# SWM320 register map
File version: 1.0
CPU: CM0 r1p0, little endian, 2 interrupt priority bits
Registers are 32-bit, read-write, no defined reset value unless marked. A register's access mark holds for its fields unless they carry their own. Offsets are from the block's base; [hi:lo] are bit positions; lines under a group give offsets from that group; {n}, {i} and the like mark numbered series; 'fields as' and 'values as' point back to an identical list.

## PWMG — Registers group
Base 0x4001A180
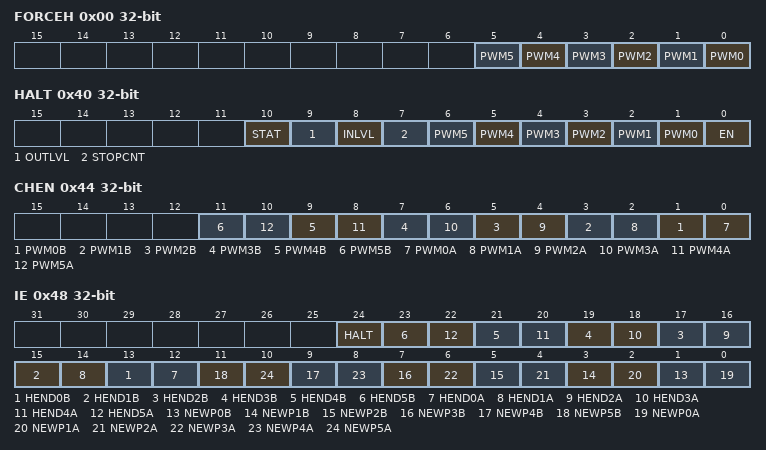
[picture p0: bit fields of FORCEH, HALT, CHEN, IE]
0x00 FORCEH
  [n] PWM{n} (n=0..5)
{0x4+8i} ADTRG{i}A (i=0..5)
{0x8+8i} ADTRG{i}B (i=0..5)
0x40 HALT
  [10] STAT, [9] OUTLVL, [8] INLVL, [7] STOPCNT, [n+1] PWM{n} (n=0..5), [0] EN
0x44 CHEN
  [2n+1] PWM{n}B (n=0..5), [2n] PWM{n}A (n=0..5)
0x48 IE
  [24] HALT, [2n+13] HEND{n}B (n=0..5), [2n+12] HEND{n}A (n=0..5), [2n+1] NEWP{n}B (n=0..5), [2n] NEWP{n}A (n=0..5)
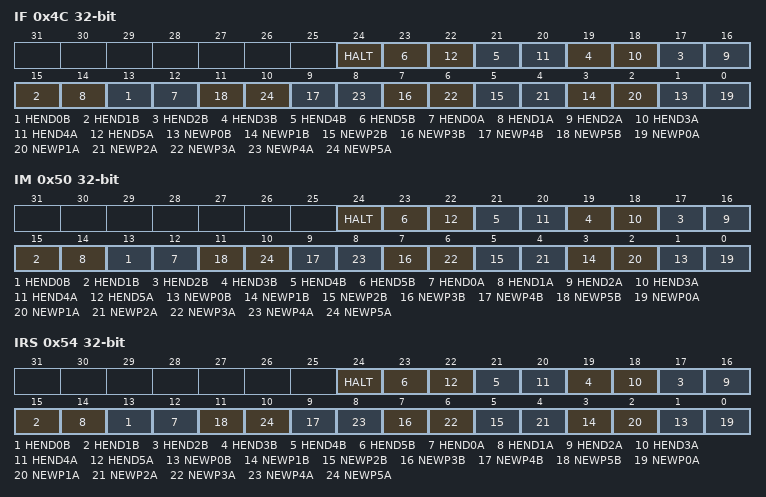
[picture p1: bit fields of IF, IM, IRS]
0x4C IF
  fields as IE
0x50 IM
  fields as IE
0x54 IRS
  fields as IE

## SDIO — Registers group
Base 0x40004000
0x00 DMA_MEM_ADDR
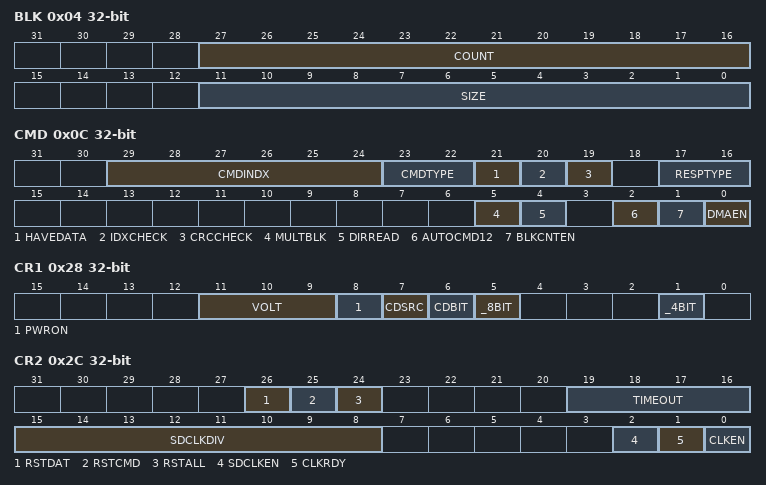
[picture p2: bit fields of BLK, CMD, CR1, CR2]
0x04 BLK
  [27:16] COUNT, [11:0] SIZE
0x08 ARG
0x0C CMD
  [29:24] CMDINDX, [23:22] CMDTYPE, [21] HAVEDATA, [20] IDXCHECK, [19] CRCCHECK, [17:16] RESPTYPE, [5] MULTBLK, [4] DIRREAD, [2] AUTOCMD12, [1] BLKCNTEN, [0] DMAEN
{0x10+4i} RESP[{i}] (i=0..3)
0x20 DATA
0x24 STAT
0x28 CR1
  [11:9] VOLT, [8] PWRON, [7] CDSRC, [6] CDBIT, [5] _8BIT, [1] _4BIT
0x2C CR2
  [26] RSTDAT, [25] RSTCMD, [24] RSTALL, [19:16] TIMEOUT, [15:8] SDCLKDIV, [2] SDCLKEN, [1] CLKRDY, [0] CLKEN
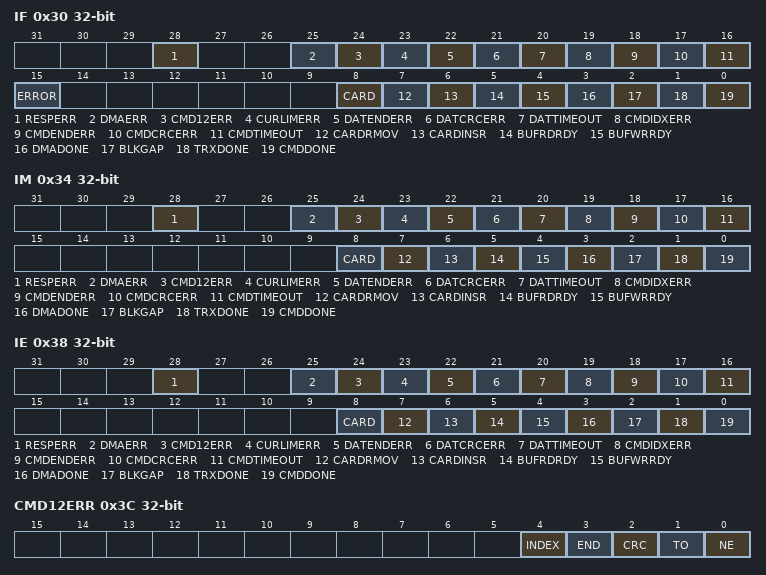
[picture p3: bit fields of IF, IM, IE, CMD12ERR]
0x30 IF
  [28] RESPERR, [25] DMAERR, [24] CMD12ERR, [23] CURLIMERR, [22] DATENDERR, [21] DATCRCERR, [20] DATTIMEOUT, [19] CMDIDXERR, [18] CMDENDERR, [17] CMDCRCERR, [16] CMDTIMEOUT, [15] ERROR, [8] CARD, [7] CARDRMOV, [6] CARDINSR, [5] BUFRDRDY, [4] BUFWRRDY, [3] DMADONE, [2] BLKGAP, [1] TRXDONE, [0] CMDDONE
0x34 IM
  [28] RESPERR, [25] DMAERR, [24] CMD12ERR, [23] CURLIMERR, [22] DATENDERR, [21] DATCRCERR, [20] DATTIMEOUT, [19] CMDIDXERR, [18] CMDENDERR, [17] CMDCRCERR, [16] CMDTIMEOUT, [8] CARD, [7] CARDRMOV, [6] CARDINSR, [5] BUFRDRDY, [4] BUFWRRDY, [3] DMADONE, [2] BLKGAP, [1] TRXDONE, [0] CMDDONE
0x38 IE
  fields as IM
0x3C CMD12ERR
  [4] INDEX, [3] END, [2] CRC, [1] TO, [0] NE

## DMA — Registers group
Base 0x40001000
0x00 EN
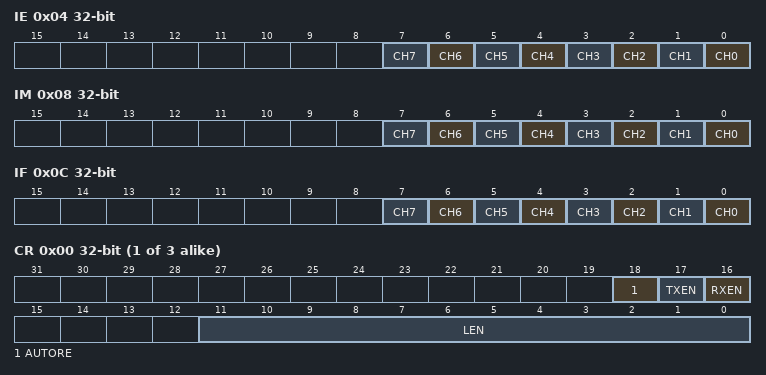
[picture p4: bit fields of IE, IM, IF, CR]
0x04 IE
  [n] CH{n} (n=0..7)
0x08 IM
  [n] CH{n} (n=0..7)
0x0C IF
  [n] CH{n} (n=0..7)
{0x40+0x40*i} CH{i} group (i=0..2) — register cluster
  0x00 CR
    [18] AUTORE, [17] TXEN, [16] RXEN, [11:0] LEN
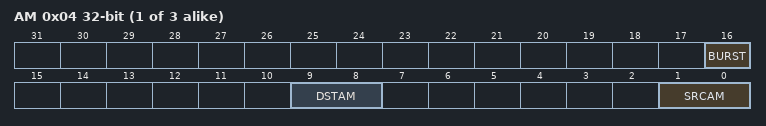
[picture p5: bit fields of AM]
  0x04 AM
    [16] BURST, [9:8] DSTAM, [1:0] SRCAM
  0x08 SRC
  {0x8+4j} SRCSGADDR{j} (j=1..3)
  0x18 SRCSGLEN
  0x1C DST
  {0x1C+4j} DSTSGADDR{j} (j=1..3)
  0x2C DSTSGLEN

## CAN — Registers group
Base 0x40030000
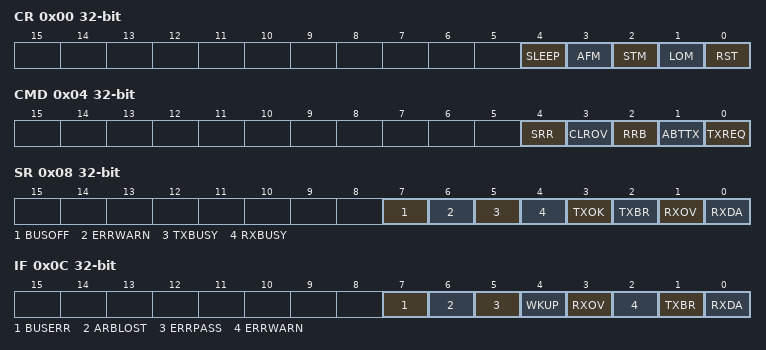
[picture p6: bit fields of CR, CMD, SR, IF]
0x00 CR
  [4] SLEEP, [3] AFM, [2] STM, [1] LOM, [0] RST
0x04 CMD wo
  [4] SRR, [3] CLROV, [2] RRB, [1] ABTTX, [0] TXREQ
0x08 SR ro
  [7] BUSOFF, [6] ERRWARN, [5] TXBUSY, [4] RXBUSY, [3] TXOK, [2] TXBR, [1] RXOV, [0] RXDA
0x0C IF ro
  [7] BUSERR, [6] ARBLOST, [5] ERRPASS, [4] WKUP, [3] RXOV, [2] ERRWARN, [1] TXBR, [0] RXDA
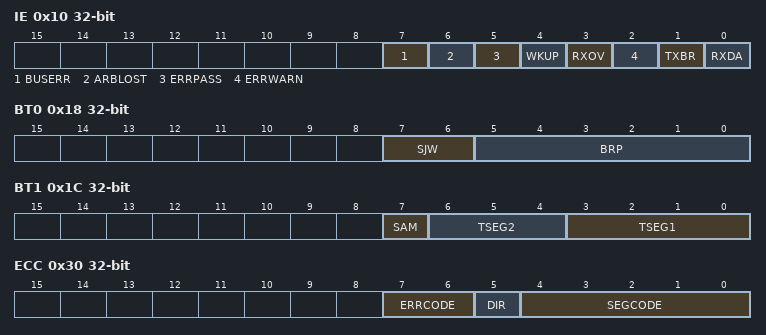
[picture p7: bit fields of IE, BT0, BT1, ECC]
0x10 IE
  fields as IF
0x18 BT0
  [7:6] SJW, [5:0] BRP
0x1C BT1
  [7] SAM, [6:4] TSEG2, [3:0] TSEG1
0x2C ALC ro
0x30 ECC ro
  [7:6] ERRCODE, [5] DIR, [4:0] SEGCODE
0x34 EWLIM
0x38 RXERR
0x3C TXERR
0x40 FILTER group — register cluster
  {0x0+4j} ACR[{j}] (j=0..3)
  {0x10+4j} AMR[{j}] (j=0..3)
0x40 FRAME group (alternate view of FILTER) — register cluster
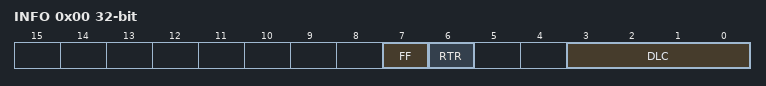
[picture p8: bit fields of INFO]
  0x00 INFO
    [7] FF, [6] RTR, [3:0] DLC
  {0x4+4j} DATA[{j}] (j=0..11)
0x74 RMCNT ro
0x180 TXFRAME_R group — register cluster
  0x00 INFO ro
    [7] FF, [6] RTR, [3:0] DLC
  {0x4+4j} DATA[{j}] (j=0..11) ro

## LCD — Registers group
Base 0x40002000
0x00 IE
0x04 IF
0x08 IM
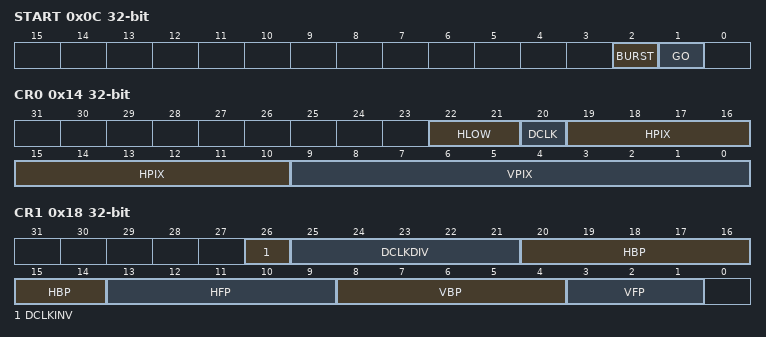
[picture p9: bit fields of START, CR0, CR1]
0x0C START
  [2] BURST, [1] GO
0x10 SRCADDR
0x14 CR0
  [22:21] HLOW, [20] DCLK, [19:10] HPIX, [9:0] VPIX
0x18 CR1
  [26] DCLKINV, [25:21] DCLKDIV, [20:14] HBP, [13:9] HFP, [8:4] VBP, [3:1] VFP
0x1C PRECMDV

## CRC — Registers group
Base 0x40003000
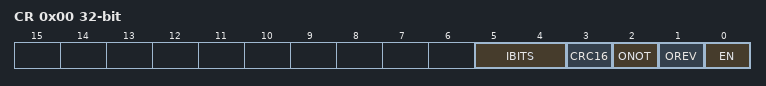
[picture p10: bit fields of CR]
0x00 CR
  [5:4] IBITS, [3] CRC16, [2] ONOT, [1] OREV, [0] EN
0x04 DATAIN wo
0x08 INIVAL
0x0C RESULT ro

## RTC — Registers group
Base 0x4001B000
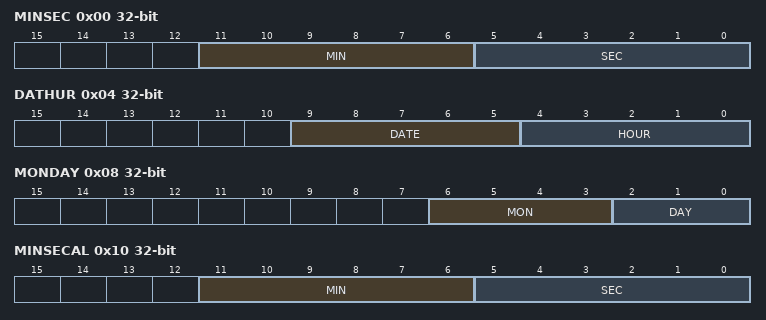
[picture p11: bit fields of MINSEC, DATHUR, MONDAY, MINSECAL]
0x00 MINSEC
  [11:6] MIN, [5:0] SEC
0x04 DATHUR
  [9:5] DATE, [4:0] HOUR
0x08 MONDAY
  [6:3] MON, [2:0] DAY
0x0C YEAR
0x10 MINSECAL
  [11:6] MIN, [5:0] SEC
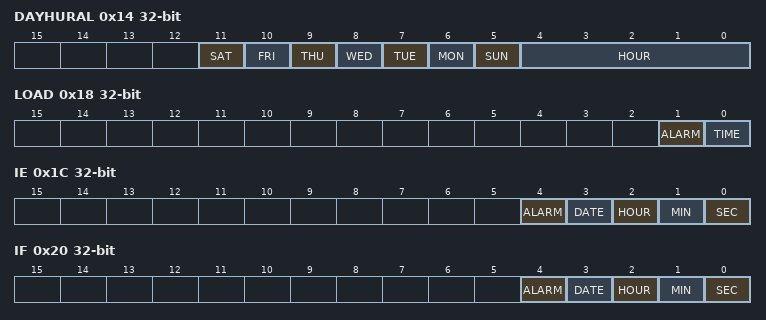
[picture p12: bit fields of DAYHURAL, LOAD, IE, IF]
0x14 DAYHURAL
  [11] SAT, [10] FRI, [9] THU, [8] WED, [7] TUE, [6] MON, [5] SUN, [4:0] HOUR
0x18 LOAD
  [1] ALARM, [0] TIME
0x1C IE
  [4] ALARM, [3] DATE, [2] HOUR, [1] MIN, [0] SEC
0x20 IF
  [4] ALARM, [3] DATE, [2] HOUR, [1] MIN, [0] SEC
0x24 EN
0x28 CFGABLE
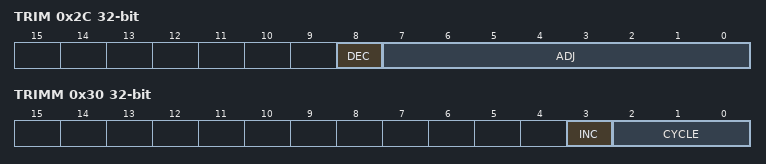
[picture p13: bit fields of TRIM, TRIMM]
0x2C TRIM
  [8] DEC, [7:0] ADJ
0x30 TRIMM
  [3] INC, [2:0] CYCLE

## WDT — Registers group
Base 0x40019000
0x00 LOAD
0x04 VALUE ro
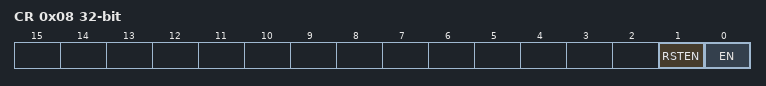
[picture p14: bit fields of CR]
0x08 CR
  [1] RSTEN, [0] EN
0x0C IF
0x10 FEED

## SRAMC — Registers group
Base 0x68000000
0x00 DATA
0x04 ADDR
0x08 ERASE
0x0C CACHE
{0x10+4i} CFG{i} (i=0..3)
0x20 STAT
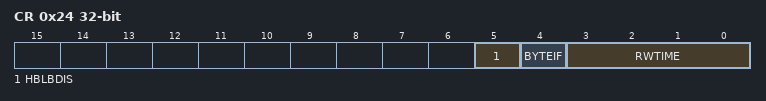
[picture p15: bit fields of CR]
0x24 CR
  [5] HBLBDIS, [4] BYTEIF, [3:0] RWTIME

## NORFLC — Registers group
Base 0x60000000
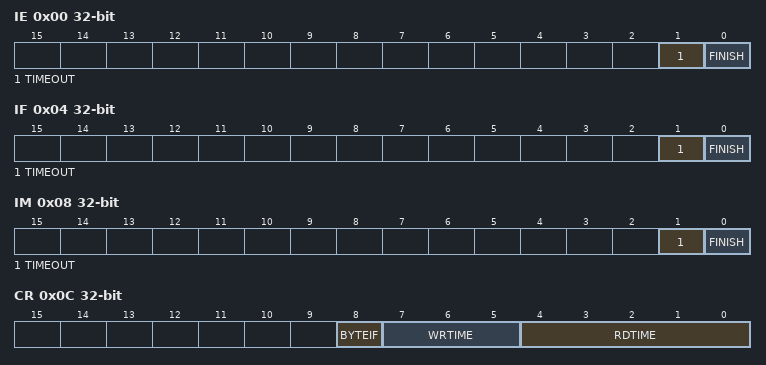
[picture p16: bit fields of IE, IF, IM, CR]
0x00 IE
  [1] TIMEOUT, [0] FINISH
0x04 IF
  [1] TIMEOUT, [0] FINISH
0x08 IM
  [1] TIMEOUT, [0] FINISH
0x0C CR
  [8] BYTEIF, [7:5] WRTIME, [4:0] RDTIME
0x10 ADDR
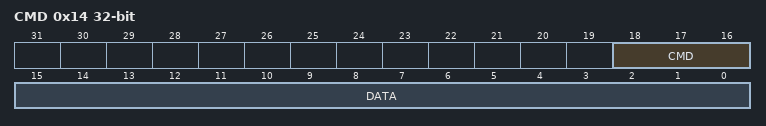
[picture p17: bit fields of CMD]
0x14 CMD
  [18:16] CMD, [15:0] DATA

## SDRAMC — Registers group
Base 0x78000000
0x00 CR0
  [6:4] CASDELAY, [2:0] BURSTLEN
0x04 CR1
  [22:21] CELLSIZE, [20] CELL32BIT, [19] BANK, [18] _32BIT, [17:15] TMRD, [14:13] TRRD, [12:10] TRAS, [9:6] TRC, [5:3] TRCD, [2:0] TRP
0x08 REFRESH
  [12] EN, [11:0] RATE
0x0C NOPNUM
0x10 LATCH
  [2] WAITST, [1] OUTEDGE, [0] INEDGE
0x14 REFDONE
